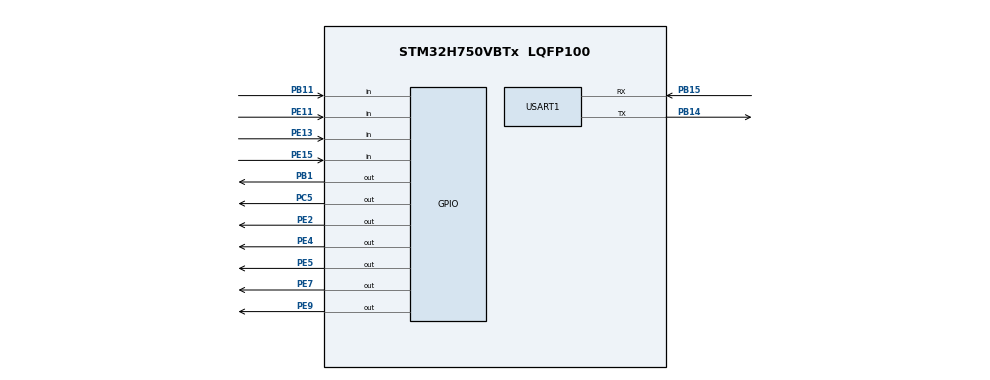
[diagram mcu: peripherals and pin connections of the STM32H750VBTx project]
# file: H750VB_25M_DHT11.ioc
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Mcu.Family=STM32H7
PE15.GPIO_Mode=GPIO_MODE_INPUT
PE7.GPIO_PuPd=GPIO_PULLUP
PE4.GPIO_ModeDefaultOutputPP=GPIO_MODE_OUTPUT_PP
RCC.CortexFreq_Value=480000000
RCC.HPRE=RCC_HCLK_DIV2
PH0-OSC_IN\ (PH0).Signal=RCC_OSC_IN
PC15-OSC32_OUT\ (OSC32_OUT).Mode=LSE-External-Oscillator
RCC.PLLFRACN=0
PE2.GPIO_Speed=GPIO_SPEED_FREQ_VERY_HIGH
PE9.GPIO_Speed=GPIO_SPEED_FREQ_VERY_HIGH
PB11.GPIO_PuPd=GPIO_PULLDOWN
PB11.Signal=GPIO_Input
PB15.Signal=USART1_RX
RCC.SYSCLKSource=RCC_SYSCLKSOURCE_PLLCLK
ProjectManager.StackSize=0x400
PE13.GPIO_Mode=GPIO_MODE_INPUT
PA14\ (JTCK/SWCLK).Signal=DEBUG_JTCK-SWCLK
PE5.GPIO_PuPd=GPIO_PULLUP
PE11.GPIO_PuPd=GPIO_PULLDOWN
PB1.GPIO_PuPd=GPIO_PULLUP
RCC.HCLKFreq_Value=240000000
PE5.Signal=GPIO_Output
PH1-OSC_OUT\ (PH1).Mode=HSE-External-Oscillator
RCC.DIVM1=5
PE13.GPIO_PuPd=GPIO_PULLDOWN
PE13.Signal=GPIO_Input
PB1.GPIO_Speed=GPIO_SPEED_FREQ_VERY_HIGH
PE9.Signal=GPIO_Output
PE4.GPIO_Speed=GPIO_SPEED_FREQ_VERY_HIGH
PB14.Mode=Asynchronous
PE5.PinState=GPIO_PIN_SET
PE2.Signal=GPIO_Output
PA14\ (JTCK/SWCLK).Mode=Serial_Wire
PE4.Signal=GPIO_Output
RCC.APB3Freq_Value=120000000
PB1.PinState=GPIO_PIN_SET
Mcu.Package=LQFP100
PB1.Signal=GPIO_Output
RCC.D1PPRE=RCC_APB3_DIV2
PC14-OSC32_IN\ (OSC32_IN).Mode=LSE-External-Oscillator
RCC.APB4Freq_Value=120000000
PC5.Signal=GPIO_Output
PE7.Signal=GPIO_Output
PB11.GPIO_Mode=GPIO_MODE_INPUT
NVIC.USART1_IRQn=true\:0\:0\:false\:false\:true\:true\:true
PE9.PinState=GPIO_PIN_SET
PH0-OSC_IN\ (PH0).Mode=HSE-External-Oscillator
RCC.PLLSourceVirtual=RCC_PLLSOURCE_HSE
PA13\ (JTMS/SWDIO).Mode=Serial_Wire
PE2.PinState=GPIO_PIN_SET
RCC.D2PPRE2=RCC_APB2_DIV2
RCC.D2PPRE1=RCC_APB1_DIV2
PE7.PinState=GPIO_PIN_SET
PC5.GPIO_PuPd=GPIO_PULLUP
PH1-OSC_OUT\ (PH1).Signal=RCC_OSC_OUT
USART1.VirtualMode-Asynchronous=VM_ASYNC
ProjectManager.TargetToolchain=MDK-ARM V5.27
PC15-OSC32_OUT\ (OSC32_OUT).Signal=RCC_OSC32_OUT
RCC.DIVN1=192
RCC.USBFreq_Value=480000000
PE11.Signal=GPIO_Input
PB14.Signal=USART1_TX
PE2.GPIO_PuPd=GPIO_PULLUP
board=custom
PB15.Mode=Asynchronous
PE7.GPIO_Speed=GPIO_SPEED_FREQ_VERY_HIGH
RCC.APB2Freq_Value=120000000
PE15.Signal=GPIO_Input
RCC.ADCFreq_Value=50390625
PE11.GPIO_Mode=GPIO_MODE_INPUT
Mcu.Name=STM32H750VBTx
PE4.GPIO_PuPd=GPIO_PULLUP
RCC.SYSCLKFreq_VALUE=480000000
PC5.PinState=GPIO_PIN_SET
PC14-OSC32_IN\ (OSC32_IN).Signal=RCC_OSC32_IN
PE15.GPIO_PuPd=GPIO_PULLDOWN
ProjectManager.HeapSize=0x200
PE5.GPIO_ModeDefaultOutputPP=GPIO_MODE_OUTPUT_PP
NVIC.PriorityGroup=NVIC_PRIORITYGROUP_4
PC5.GPIO_Speed=GPIO_SPEED_FREQ_VERY_HIGH
PE5.GPIO_Speed=GPIO_SPEED_FREQ_VERY_HIGH
PE4.PinState=GPIO_PIN_SET
RCC.D3PPRE=RCC_APB4_DIV2
PE7.GPIO_ModeDefaultOutputPP=GPIO_MODE_OUTPUT_PP
PE9.GPIO_ModeDefaultOutputPP=GPIO_MODE_OUTPUT_PP
PB1.GPIO_ModeDefaultOutputPP=GPIO_MODE_OUTPUT_PP
RCC.APB1Freq_Value=120000000
PC5.GPIO_ModeDefaultOutputPP=GPIO_MODE_OUTPUT_PP
PA13\ (JTMS/SWDIO).Signal=DEBUG_JTMS-SWDIO
PE9.GPIO_PuPd=GPIO_PULLUP

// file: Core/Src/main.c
/* USER CODE BEGIN Header */
/**
  ******************************************************************************
  * @file           : main.c
  * @brief          : Main program body
  ******************************************************************************
  * @attention
  *
  * <h2><center>&copy; Copyright (c) 2020 STMicroelectronics.
  * All rights reserved.</center></h2>
  *
  * This software component is licensed by ST under BSD 3-Clause license,
  * the "License"; You may not use this file except in compliance with the
  * License. You may obtain a copy of the License at:
  *                        opensource.org/licenses/BSD-3-Clause
  *
  ******************************************************************************
  */
/* USER CODE END Header */
#include "main.h"
#include "usart.h"
#include "gpio.h"

/* USER CODE BEGIN Includes */
#include "OLED/oled_iic.h"
#include "DHT11/dht11.h"
#include "DELAY/delay.h"
/* USER CODE END Includes */

void SystemClock_Config(void);

int main(void)
{

  /* MCU Configuration--------------------------------------------------------*/

  /* Reset of all peripherals, Initializes the Flash interface and the Systick. */
  HAL_Init();

  /* Configure the system clock */
  SystemClock_Config();

  /* Initialize all configured peripherals */
  MX_GPIO_Init();
  MX_USART1_UART_Init();
  /* USER CODE BEGIN 2 */
    Delay_Init(480);
    OLED_Init();
    DHT11_Init();
  /* USER CODE END 2 */

  /* Infinite loop */
  while (1)
  {

    /* USER CODE BEGIN 3 */
      Delay_ms(500);
      if(!DHT11_Refresh())
          continue;
      OLED_CLS();
      OLED_ShowFloat(0,0,DHT11_GetTemp(),TEXTSIZE_SMALL,REVERSE_OFF);
      OLED_ShowFloat(0,1,DHT11_GetHumid(),TEXTSIZE_SMALL,REVERSE_OFF);
      HAL_GPIO_TogglePin(GPIOE,GPIO_PIN_6);
  }
  /* USER CODE END 3 */
}

void SystemClock_Config(void)
{
  RCC_OscInitTypeDef RCC_OscInitStruct = {0};
  RCC_ClkInitTypeDef RCC_ClkInitStruct = {0};
  RCC_PeriphCLKInitTypeDef PeriphClkInitStruct = {0};

  /** Supply configuration update enable
  */
  HAL_PWREx_ConfigSupply(PWR_LDO_SUPPLY);
  /** Configure the main internal regulator output voltage
  */
  __HAL_PWR_VOLTAGESCALING_CONFIG(PWR_REGULATOR_VOLTAGE_SCALE0);

  while(!__HAL_PWR_GET_FLAG(PWR_FLAG_VOSRDY)) {}
  /** Initializes the RCC Oscillators according to the specified parameters
  * in the RCC_OscInitTypeDef structure.
  */
  RCC_OscInitStruct.OscillatorType = RCC_OSCILLATORTYPE_HSE;
  RCC_OscInitStruct.HSEState = RCC_HSE_ON;
  RCC_OscInitStruct.PLL.PLLState = RCC_PLL_ON;
  RCC_OscInitStruct.PLL.PLLSource = RCC_PLLSOURCE_HSE;
  RCC_OscInitStruct.PLL.PLLM = 5;
  RCC_OscInitStruct.PLL.PLLN = 192;
  RCC_OscInitStruct.PLL.PLLP = 2;
  RCC_OscInitStruct.PLL.PLLQ = 2;
  RCC_OscInitStruct.PLL.PLLR = 2;
  RCC_OscInitStruct.PLL.PLLRGE = RCC_PLL1VCIRANGE_2;
  RCC_OscInitStruct.PLL.PLLVCOSEL = RCC_PLL1VCOWIDE;
  RCC_OscInitStruct.PLL.PLLFRACN = 0;
  if (HAL_RCC_OscConfig(&RCC_OscInitStruct) != HAL_OK)
  {
    Error_Handler();
  }
  /** Initializes the CPU, AHB and APB buses clocks
  */
  RCC_ClkInitStruct.ClockType = RCC_CLOCKTYPE_HCLK|RCC_CLOCKTYPE_SYSCLK
                              |RCC_CLOCKTYPE_PCLK1|RCC_CLOCKTYPE_PCLK2
                              |RCC_CLOCKTYPE_D3PCLK1|RCC_CLOCKTYPE_D1PCLK1;
  RCC_ClkInitStruct.SYSCLKSource = RCC_SYSCLKSOURCE_PLLCLK;
  RCC_ClkInitStruct.SYSCLKDivider = RCC_SYSCLK_DIV1;
  RCC_ClkInitStruct.AHBCLKDivider = RCC_HCLK_DIV2;
  RCC_ClkInitStruct.APB3CLKDivider = RCC_APB3_DIV2;
  RCC_ClkInitStruct.APB1CLKDivider = RCC_APB1_DIV2;
  RCC_ClkInitStruct.APB2CLKDivider = RCC_APB2_DIV2;
  RCC_ClkInitStruct.APB4CLKDivider = RCC_APB4_DIV2;

  if (HAL_RCC_ClockConfig(&RCC_ClkInitStruct, FLASH_LATENCY_4) != HAL_OK)
  {
    Error_Handler();
  }
  PeriphClkInitStruct.PeriphClockSelection = RCC_PERIPHCLK_USART1;
  PeriphClkInitStruct.Usart16ClockSelection = RCC_USART16CLKSOURCE_D2PCLK2;
  if (HAL_RCCEx_PeriphCLKConfig(&PeriphClkInitStruct) != HAL_OK)
  {
    Error_Handler();
  }
}

void Error_Handler(void)
{
}

/************************ (C) COPYRIGHT STMicroelectronics *****END OF FILE****/
